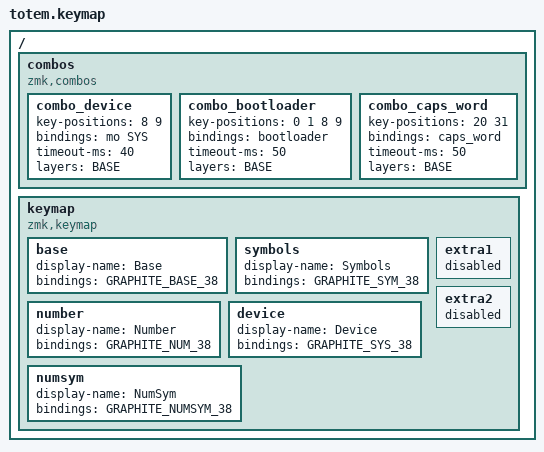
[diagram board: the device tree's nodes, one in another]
/*
 * Copyright (c) 2020 The ZMK Contributors
 *
 * SPDX-License-Identifier: MIT
 */

#include <behaviors.dtsi>
#include <dt-bindings/zmk/keys.h>
#include <dt-bindings/zmk/bt.h>
#include <dt-bindings/zmk/outputs.h>

#include "graphite.dtsi"

/ {
    combos {
        compatible = "zmk,combos";

        // U+J: hold for Device layer
        combo_device {
            key-positions = <8 9>;
            bindings = <&mo SYS>;
            timeout-ms = <40>;
            layers = <BASE>;
        };

        // U+J+B+L: bootloader
        combo_bootloader {
            key-positions = <0 1 8 9>;
            bindings = <&bootloader>;
            timeout-ms = <50>;
            layers = <BASE>;
        };

        // both shifts: caps word
        combo_caps_word {
            key-positions = <20 31>;
            bindings = <&caps_word>;
            timeout-ms = <50>;
            layers = <BASE>;
        };


    };

    keymap {
        compatible = "zmk,keymap";

        base {
            display-name = "Base";
            bindings = < GRAPHITE_BASE_38 >;
        };

        symbols {
            display-name = "Symbols";
            bindings = < GRAPHITE_SYM_38 >;
        };

        number {
            display-name = "Number";
            bindings = < GRAPHITE_NUM_38 >;
        };

        device {
            display-name = "Device";
            bindings = < GRAPHITE_SYS_38 >;
        };

        numsym {
            display-name = "NumSym";
            bindings = < GRAPHITE_NUMSYM_38 >;
        };

        extra1 { status = "reserved"; };
        extra2 { status = "reserved"; };
    };
};
